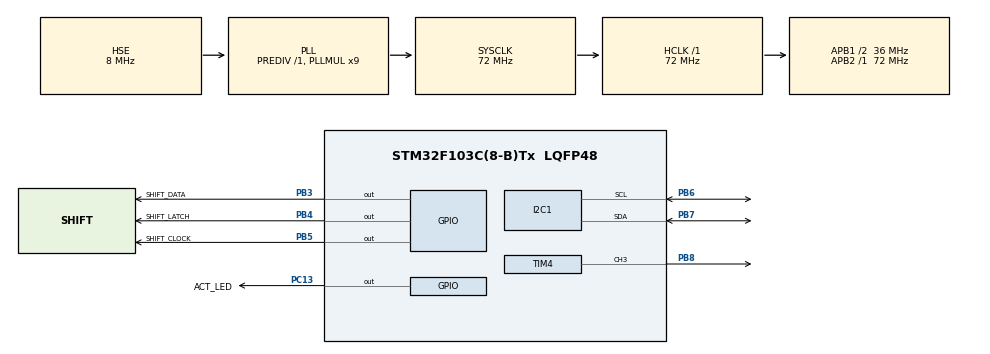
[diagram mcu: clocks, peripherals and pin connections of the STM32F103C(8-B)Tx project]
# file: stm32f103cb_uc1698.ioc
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Dma.I2C1_RX.0.Direction=DMA_PERIPH_TO_MEMORY
Dma.I2C1_RX.0.Instance=DMA1_Channel7
Dma.I2C1_RX.0.MemDataAlignment=DMA_MDATAALIGN_BYTE
Dma.I2C1_RX.0.MemInc=DMA_MINC_ENABLE
Dma.I2C1_RX.0.Mode=DMA_CIRCULAR
Dma.I2C1_RX.0.PeriphDataAlignment=DMA_PDATAALIGN_BYTE
Dma.I2C1_RX.0.PeriphInc=DMA_PINC_DISABLE
Dma.I2C1_RX.0.Priority=DMA_PRIORITY_LOW
Dma.I2C1_TX.1.Direction=DMA_MEMORY_TO_PERIPH
Dma.I2C1_TX.1.Instance=DMA1_Channel6
Dma.I2C1_TX.1.MemDataAlignment=DMA_MDATAALIGN_BYTE
Dma.I2C1_TX.1.MemInc=DMA_MINC_ENABLE
Dma.I2C1_TX.1.Mode=DMA_CIRCULAR
Dma.I2C1_TX.1.PeriphDataAlignment=DMA_PDATAALIGN_BYTE
Dma.I2C1_TX.1.PeriphInc=DMA_PINC_DISABLE
Dma.I2C1_TX.1.Priority=DMA_PRIORITY_LOW
Dma.Request0=I2C1_RX
Dma.Request1=I2C1_TX
I2C1.OwnAddress=0x20
Mcu.Family=STM32F1
Mcu.Name=STM32F103C(8-B)Tx
Mcu.Package=LQFP48
NVIC.DMA1_Channel6_IRQn=true\:0\:0\:false\:false\:true\:false\:true\:true
NVIC.DMA1_Channel7_IRQn=true\:0\:0\:false\:false\:true\:false\:true\:true
NVIC.I2C1_EV_IRQn=true\:0\:0\:false\:false\:true\:true\:true\:true
NVIC.PriorityGroup=NVIC_PRIORITYGROUP_4
PA13.Mode=Serial_Wire
PA13.Signal=SYS_JTMS-SWDIO
PA14.Mode=Serial_Wire
PA14.Signal=SYS_JTCK-SWCLK
PB3.GPIO_Label=SHIFT_DATA
PB3.Signal=GPIO_Output
PB4.GPIO_Label=SHIFT_LATCH
PB4.Signal=GPIO_Output
PB5.GPIO_Label=SHIFT_CLOCK
PB5.Signal=GPIO_Output
PB6.Mode=I2C
PB6.Signal=I2C1_SCL
PB7.Mode=I2C
PB7.Signal=I2C1_SDA
PB8.Signal=S_TIM4_CH3
PC13-TAMPER-RTC.GPIO_Label=ACT_LED
PC13-TAMPER-RTC.Signal=GPIO_Output
PD0-OSC_IN.Mode=HSE-External-Oscillator
PD0-OSC_IN.Signal=RCC_OSC_IN
PD1-OSC_OUT.Mode=HSE-External-Oscillator
PD1-OSC_OUT.Signal=RCC_OSC_OUT
ProjectManager.HeapSize=0x200
ProjectManager.StackSize=0x400
ProjectManager.TargetToolchain=STM32CubeIDE
RCC.AHBFreq_Value=72000000
RCC.APB1CLKDivider=RCC_HCLK_DIV2
RCC.APB1Freq_Value=36000000
RCC.APB1TimFreq_Value=72000000
RCC.APB2Freq_Value=72000000
RCC.APB2TimFreq_Value=72000000
RCC.HCLKFreq_Value=72000000
RCC.PLLMUL=RCC_PLL_MUL9
RCC.PLLSourceVirtual=RCC_PLLSOURCE_HSE
RCC.SYSCLKFreq_VALUE=72000000
RCC.SYSCLKSource=RCC_SYSCLKSOURCE_PLLCLK
RCC.USBFreq_Value=72000000
SH.S_TIM4_CH3.0=TIM4_CH3,PWM Generation3 CH3
TIM4.Channel-PWM\ Generation3\ CH3=TIM_CHANNEL_3
TIM4.Period=999
TIM4.Pulse-PWM\ Generation3\ CH3=500
VP_RTC_VS_RTC_Activate.Mode=RTC_Enabled
VP_RTC_VS_RTC_Calendar.Mode=RTC_Calendar
board=custom

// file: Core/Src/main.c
/* USER CODE BEGIN Header */
/**
  ******************************************************************************
  * @file           : main.c
  * @brief          : Main program body
  ******************************************************************************
  * @attention
  *
  * Copyright (c) 2023 STMicroelectronics.
  * All rights reserved.
  *
  * This software is licensed under terms that can be found in the LICENSE file
  * in the root directory of this software component.
  * If no LICENSE file comes with this software, it is provided AS-IS.
  *
  ******************************************************************************
  */
/* USER CODE END Header */
#include "main.h"

/* USER CODE BEGIN Includes */
#include "application.h"
/* USER CODE END Includes */

I2C_HandleTypeDef hi2c1;
DMA_HandleTypeDef hdma_i2c1_rx;
DMA_HandleTypeDef hdma_i2c1_tx;

RTC_HandleTypeDef hrtc;

TIM_HandleTypeDef htim4;

void SystemClock_Config(void);
static void MX_GPIO_Init(void);
static void MX_DMA_Init(void);
static void MX_I2C1_Init(void);
static void MX_RTC_Init(void);
static void MX_TIM4_Init(void);

int main(void)
{

  /* MCU Configuration--------------------------------------------------------*/

  /* Reset of all peripherals, Initializes the Flash interface and the Systick. */
  HAL_Init();

  /* Configure the system clock */
  SystemClock_Config();

  /* Initialize all configured peripherals */
  MX_GPIO_Init();
  MX_DMA_Init();
  MX_I2C1_Init();
  MX_RTC_Init();
  MX_TIM4_Init();
  /* USER CODE BEGIN 2 */
  Application.init();

  /* USER CODE END 2 */

  /* Infinite loop */
  while (1)
  {

    /* USER CODE BEGIN 3 */
	  Application.loop();

  }
  /* USER CODE END 3 */
}

void SystemClock_Config(void)
{
  RCC_OscInitTypeDef RCC_OscInitStruct = {0};
  RCC_ClkInitTypeDef RCC_ClkInitStruct = {0};
  RCC_PeriphCLKInitTypeDef PeriphClkInit = {0};

  /** Initializes the RCC Oscillators according to the specified parameters
  * in the RCC_OscInitTypeDef structure.
  */
  RCC_OscInitStruct.OscillatorType = RCC_OSCILLATORTYPE_LSI|RCC_OSCILLATORTYPE_HSE;
  RCC_OscInitStruct.HSEState = RCC_HSE_ON;
  RCC_OscInitStruct.HSEPredivValue = RCC_HSE_PREDIV_DIV1;
  RCC_OscInitStruct.HSIState = RCC_HSI_ON;
  RCC_OscInitStruct.LSIState = RCC_LSI_ON;
  RCC_OscInitStruct.PLL.PLLState = RCC_PLL_ON;
  RCC_OscInitStruct.PLL.PLLSource = RCC_PLLSOURCE_HSE;
  RCC_OscInitStruct.PLL.PLLMUL = RCC_PLL_MUL9;
  if (HAL_RCC_OscConfig(&RCC_OscInitStruct) != HAL_OK)
  {
    Error_Handler();
  }

  /** Initializes the CPU, AHB and APB buses clocks
  */
  RCC_ClkInitStruct.ClockType = RCC_CLOCKTYPE_HCLK|RCC_CLOCKTYPE_SYSCLK
                              |RCC_CLOCKTYPE_PCLK1|RCC_CLOCKTYPE_PCLK2;
  RCC_ClkInitStruct.SYSCLKSource = RCC_SYSCLKSOURCE_PLLCLK;
  RCC_ClkInitStruct.AHBCLKDivider = RCC_SYSCLK_DIV1;
  RCC_ClkInitStruct.APB1CLKDivider = RCC_HCLK_DIV2;
  RCC_ClkInitStruct.APB2CLKDivider = RCC_HCLK_DIV1;

  if (HAL_RCC_ClockConfig(&RCC_ClkInitStruct, FLASH_LATENCY_2) != HAL_OK)
  {
    Error_Handler();
  }
  PeriphClkInit.PeriphClockSelection = RCC_PERIPHCLK_RTC;
  PeriphClkInit.RTCClockSelection = RCC_RTCCLKSOURCE_LSI;
  if (HAL_RCCEx_PeriphCLKConfig(&PeriphClkInit) != HAL_OK)
  {
    Error_Handler();
  }
}

static void MX_I2C1_Init(void)
{

  hi2c1.Instance = I2C1;
  hi2c1.Init.ClockSpeed = 100000;
  hi2c1.Init.DutyCycle = I2C_DUTYCYCLE_2;
  hi2c1.Init.OwnAddress1 = 64;
  hi2c1.Init.AddressingMode = I2C_ADDRESSINGMODE_7BIT;
  hi2c1.Init.DualAddressMode = I2C_DUALADDRESS_DISABLE;
  hi2c1.Init.OwnAddress2 = 0;
  hi2c1.Init.GeneralCallMode = I2C_GENERALCALL_DISABLE;
  hi2c1.Init.NoStretchMode = I2C_NOSTRETCH_DISABLE;
  if (HAL_I2C_Init(&hi2c1) != HAL_OK)
  {
    Error_Handler();
  }

}

static void MX_RTC_Init(void)
{

  RTC_TimeTypeDef sTime = {0};
  RTC_DateTypeDef DateToUpdate = {0};

  /** Initialize RTC Only
  */
  hrtc.Instance = RTC;
  hrtc.Init.AsynchPrediv = RTC_AUTO_1_SECOND;
  hrtc.Init.OutPut = RTC_OUTPUTSOURCE_ALARM;
  if (HAL_RTC_Init(&hrtc) != HAL_OK)
  {
    Error_Handler();
  }

  /** Initialize RTC and set the Time and Date
  */
  sTime.Hours = 0x0;
  sTime.Minutes = 0x0;
  sTime.Seconds = 0x0;

  if (HAL_RTC_SetTime(&hrtc, &sTime, RTC_FORMAT_BCD) != HAL_OK)
  {
    Error_Handler();
  }
  DateToUpdate.WeekDay = RTC_WEEKDAY_MONDAY;
  DateToUpdate.Month = RTC_MONTH_JANUARY;
  DateToUpdate.Date = 0x1;
  DateToUpdate.Year = 0x0;

  if (HAL_RTC_SetDate(&hrtc, &DateToUpdate, RTC_FORMAT_BCD) != HAL_OK)
  {
    Error_Handler();
  }

}

static void MX_TIM4_Init(void)
{

  TIM_MasterConfigTypeDef sMasterConfig = {0};
  TIM_OC_InitTypeDef sConfigOC = {0};

  htim4.Instance = TIM4;
  htim4.Init.Prescaler = 0;
  htim4.Init.CounterMode = TIM_COUNTERMODE_UP;
  htim4.Init.Period = 999;
  htim4.Init.ClockDivision = TIM_CLOCKDIVISION_DIV1;
  htim4.Init.AutoReloadPreload = TIM_AUTORELOAD_PRELOAD_DISABLE;
  if (HAL_TIM_PWM_Init(&htim4) != HAL_OK)
  {
    Error_Handler();
  }
  sMasterConfig.MasterOutputTrigger = TIM_TRGO_RESET;
  sMasterConfig.MasterSlaveMode = TIM_MASTERSLAVEMODE_DISABLE;
  if (HAL_TIMEx_MasterConfigSynchronization(&htim4, &sMasterConfig) != HAL_OK)
  {
    Error_Handler();
  }
  sConfigOC.OCMode = TIM_OCMODE_PWM1;
  sConfigOC.Pulse = 500;
  sConfigOC.OCPolarity = TIM_OCPOLARITY_HIGH;
  sConfigOC.OCFastMode = TIM_OCFAST_DISABLE;
  if (HAL_TIM_PWM_ConfigChannel(&htim4, &sConfigOC, TIM_CHANNEL_3) != HAL_OK)
  {
    Error_Handler();
  }
  HAL_TIM_MspPostInit(&htim4);

}

static void MX_DMA_Init(void)
{

  /* DMA controller clock enable */
  __HAL_RCC_DMA1_CLK_ENABLE();

  /* DMA interrupt init */
  /* DMA1_Channel6_IRQn interrupt configuration */
  HAL_NVIC_SetPriority(DMA1_Channel6_IRQn, 0, 0);
  HAL_NVIC_EnableIRQ(DMA1_Channel6_IRQn);
  /* DMA1_Channel7_IRQn interrupt configuration */
  HAL_NVIC_SetPriority(DMA1_Channel7_IRQn, 0, 0);
  HAL_NVIC_EnableIRQ(DMA1_Channel7_IRQn);

}

static void MX_GPIO_Init(void)
{
  GPIO_InitTypeDef GPIO_InitStruct = {0};

  /* GPIO Ports Clock Enable */
  __HAL_RCC_GPIOC_CLK_ENABLE();
  __HAL_RCC_GPIOD_CLK_ENABLE();
  __HAL_RCC_GPIOA_CLK_ENABLE();
  __HAL_RCC_GPIOB_CLK_ENABLE();

  /*Configure GPIO pin Output Level */
  HAL_GPIO_WritePin(ACT_LED_GPIO_Port, ACT_LED_Pin, GPIO_PIN_RESET);

  /*Configure GPIO pin Output Level */
  HAL_GPIO_WritePin(GPIOB, SHIFT_DATA_Pin|SHIFT_LATCH_Pin|SHIFT_CLOCK_Pin, GPIO_PIN_RESET);

  /*Configure GPIO pin : ACT_LED_Pin */
  GPIO_InitStruct.Pin = ACT_LED_Pin;
  GPIO_InitStruct.Mode = GPIO_MODE_OUTPUT_PP;
  GPIO_InitStruct.Pull = GPIO_NOPULL;
  GPIO_InitStruct.Speed = GPIO_SPEED_FREQ_LOW;
  HAL_GPIO_Init(ACT_LED_GPIO_Port, &GPIO_InitStruct);

  /*Configure GPIO pins : SHIFT_DATA_Pin SHIFT_LATCH_Pin SHIFT_CLOCK_Pin */
  GPIO_InitStruct.Pin = SHIFT_DATA_Pin|SHIFT_LATCH_Pin|SHIFT_CLOCK_Pin;
  GPIO_InitStruct.Mode = GPIO_MODE_OUTPUT_PP;
  GPIO_InitStruct.Pull = GPIO_NOPULL;
  GPIO_InitStruct.Speed = GPIO_SPEED_FREQ_LOW;
  HAL_GPIO_Init(GPIOB, &GPIO_InitStruct);

}

void Error_Handler(void)
{
  __disable_irq();
  while (1)
  {
  }
}
